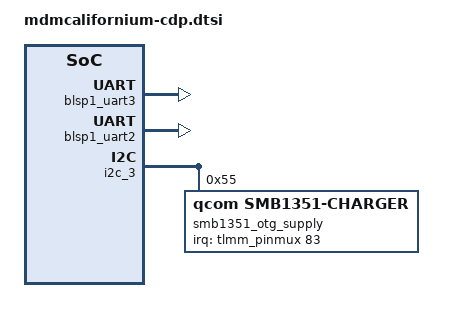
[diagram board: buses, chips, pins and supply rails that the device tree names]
/* Copyright (c) 2015, The Linux Foundation. All rights reserved.
 *
 * This program is free software; you can redistribute it and/or modify
 * it under the terms of the GNU General Public License version 2 and
 * only version 2 as published by the Free Software Foundation.
 *
 * This program is distributed in the hope that it will be useful,
 * but WITHOUT ANY WARRANTY; without even the implied warranty of
 * MERCHANTABILITY or FITNESS FOR A PARTICULAR PURPOSE.  See the
 * GNU General Public License for more details.
 */

#include "mdmcalifornium.dtsi"
#include "mdmcalifornium-pinctrl.dtsi"

&blsp1_uart3 {
	status = "ok";
	pinctrl-names = "default";
	pinctrl-0 = <&uart3_console_active>;
};

&blsp1_uart2 {
	status = "ok";
	pinctrl-names = "default";
	pinctrl-0 = <&uart2_console_active>;

};

&i2c_3 {
	status = "ok";
	smb1351_otg_supply: smb1351-charger@55 {
		compatible = "qcom,smb1351-charger";
		reg = <0x55>;
		interrupt-parent = <&tlmm_pinmux>;
		interrupts = <83 0>;
		qcom,float-voltage-mv = <4200>;
		qcom,charging-timeout = <1536>;
		qcom,recharge-thresh-mv = <200>;
		qcom,iterm-ma = <100>;
		regulator-name = "smb1351_otg_supply";
		qcom,charging-disabled;
		qcom,id-line-not-connected;
	};
};

&usb3 {
	vbus_dwc3-supply = <&smb1351_otg_supply>;
};
